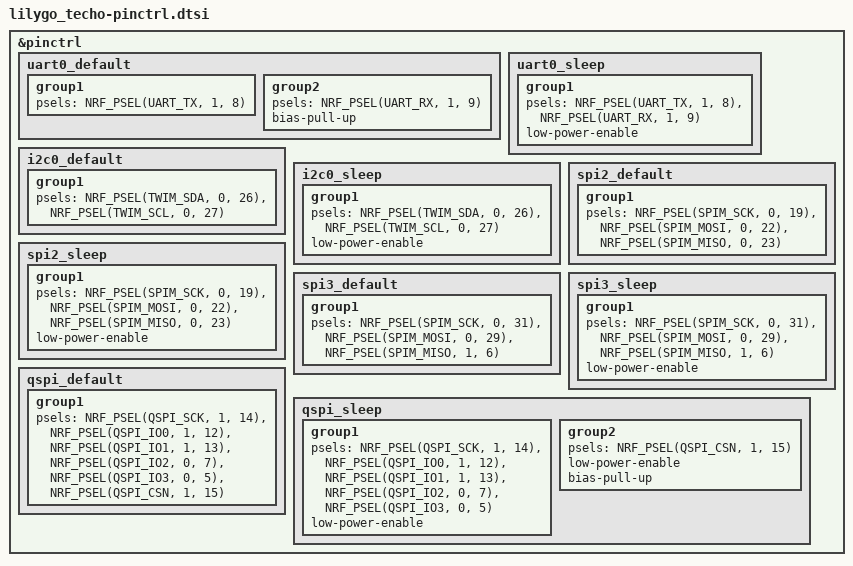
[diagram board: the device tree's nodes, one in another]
/*
 * LilyGo T-Echo pin control definitions
 * Copyright (c) 2026 ZephCore
 *
 * SPDX-License-Identifier: Apache-2.0
 *
 * Pin mappings (from Arduino MeshCore variant.h):
 *
 * SPI2 (LoRa SX1262):   SCK=P0.19, MISO=P0.23, MOSI=P0.22, CS=P0.24
 * SPI3 (EPD SSD1681):   SCK=P0.31, MISO=P1.06, MOSI=P0.29
 * I2C0 (BME280):        SDA=P0.26, SCL=P0.27
 * UART0 (L76K GPS 9600):TX=P1.08 (→GPS RX), RX=P1.09 (←GPS TX)
 * QSPI (MX25R1635F):    SCK=P1.14, CS=P1.15, IO0=P1.12, IO1=P1.13,
 *                       IO2=P0.07, IO3=P0.05
 */

&pinctrl {
	/* UART0 for L76K GPS at 9600 baud */
	uart0_default: uart0_default {
		group1 {
			psels = <NRF_PSEL(UART_TX, 1, 8)>;   /* P1.08 → GPS RX */
		};
		group2 {
			psels = <NRF_PSEL(UART_RX, 1, 9)>;   /* P1.09 ← GPS TX */
			bias-pull-up;
		};
	};

	uart0_sleep: uart0_sleep {
		group1 {
			psels = <NRF_PSEL(UART_TX, 1, 8)>,
				<NRF_PSEL(UART_RX, 1, 9)>;
			low-power-enable;
		};
	};

	/* I2C0 for BME280 sensor */
	i2c0_default: i2c0_default {
		group1 {
			psels = <NRF_PSEL(TWIM_SDA, 0, 26)>,   /* P0.26 */
				<NRF_PSEL(TWIM_SCL, 0, 27)>;  /* P0.27 */
		};
	};

	i2c0_sleep: i2c0_sleep {
		group1 {
			psels = <NRF_PSEL(TWIM_SDA, 0, 26)>,
				<NRF_PSEL(TWIM_SCL, 0, 27)>;
			low-power-enable;
		};
	};

	/* SPI2 for LoRa SX1262 */
	spi2_default: spi2_default {
		group1 {
			psels = <NRF_PSEL(SPIM_SCK,  0, 19)>,   /* P0.19 */
				<NRF_PSEL(SPIM_MOSI, 0, 22)>,  /* P0.22 */
				<NRF_PSEL(SPIM_MISO, 0, 23)>;  /* P0.23 */
		};
	};

	spi2_sleep: spi2_sleep {
		group1 {
			psels = <NRF_PSEL(SPIM_SCK,  0, 19)>,
				<NRF_PSEL(SPIM_MOSI, 0, 22)>,
				<NRF_PSEL(SPIM_MISO, 0, 23)>;
			low-power-enable;
		};
	};

	/* SPI3 for E-Paper SSD1681 — MISO is routed on T-Echo (P1.06)
	 * even though the SSD1681 is write-only; Nordic SPIM needs MISO
	 * configured to avoid driver config errors. */
	spi3_default: spi3_default {
		group1 {
			psels = <NRF_PSEL(SPIM_SCK,  0, 31)>,   /* P0.31 */
				<NRF_PSEL(SPIM_MOSI, 0, 29)>,  /* P0.29 */
				<NRF_PSEL(SPIM_MISO, 1, 6)>;   /* P1.06 */
		};
	};

	spi3_sleep: spi3_sleep {
		group1 {
			psels = <NRF_PSEL(SPIM_SCK,  0, 31)>,
				<NRF_PSEL(SPIM_MOSI, 0, 29)>,
				<NRF_PSEL(SPIM_MISO, 1, 6)>;
			low-power-enable;
		};
	};

	/* QSPI for MX25R1635F 2MB external flash — identical pin routing
	 * to ThinkNode M1, T-Echo re-uses Adafruit's reference layout. */
	qspi_default: qspi_default {
		group1 {
			psels = <NRF_PSEL(QSPI_SCK, 1, 14)>,
				<NRF_PSEL(QSPI_IO0, 1, 12)>,
				<NRF_PSEL(QSPI_IO1, 1, 13)>,
				<NRF_PSEL(QSPI_IO2, 0, 7)>,
				<NRF_PSEL(QSPI_IO3, 0, 5)>,
				<NRF_PSEL(QSPI_CSN, 1, 15)>;
		};
	};

	qspi_sleep: qspi_sleep {
		group1 {
			psels = <NRF_PSEL(QSPI_SCK, 1, 14)>,
				<NRF_PSEL(QSPI_IO0, 1, 12)>,
				<NRF_PSEL(QSPI_IO1, 1, 13)>,
				<NRF_PSEL(QSPI_IO2, 0, 7)>,
				<NRF_PSEL(QSPI_IO3, 0, 5)>;
			low-power-enable;
		};
		group2 {
			psels = <NRF_PSEL(QSPI_CSN, 1, 15)>;
			low-power-enable;
			bias-pull-up;
		};
	};
};
